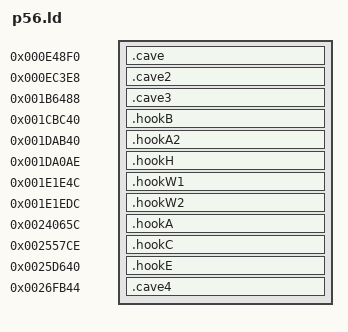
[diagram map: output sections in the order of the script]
SECTIONS {
  .cave 0xe48f0 : { *(.cave) }
  .cave2 0xec3e8 : { *(.cave2) }
  .cave3 0x1b6488 : { *(.cave3) }
  .hookB 0x1cbc40 : { *(.hookB) }
  .hookA2 0x1dab40 : { *(.hookA2) }
  .hookH 0x1da0ae : { *(.hookH) }
  .hookW1 0x1e1e4c : { *(.hookW1) }
  .hookW2 0x1e1edc : { *(.hookW2) }
  .hookA 0x24065c : { *(.hookA) }
  .hookC 0x2557ce : { *(.hookC) }
  .hookE 0x25d640 : { *(.hookE) }
  .cave4 0x26fb44 : { *(.cave4) }
}
LM = 0x499cc0; EVT = 0x4a8330; COTD = 0x3db03a;
POST = 0xfa779; STRCPY = 0x3a2178; W52 = 0x1cbc53; W48 = 0x1cbc49;
ENT = 0xf6995; GETDOOR = 0x1b49f9; FAIL = 0x255773; RESUME = 0x2557d5;
WK1 = 0x1e1e5f; WN1 = 0x1e1e55; WK2 = 0x1e1eef; WN2 = 0x1e1ee5;
GETCHALK = 0x255939; HIER = 0xf5b2d; FINDCHILD = 0xf5c2b; GETREND = 0x2656fd; SETVIS = 0x265a29;
BUY = 0x2556c1;
